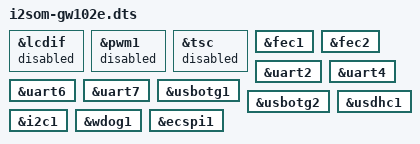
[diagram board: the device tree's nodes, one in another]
/*
 * Copyright (C) 2017 i2SOM Team.
 *
 * This program is free software; you can redistribute it and/or modify
 * it under the terms of the GNU General Public License version 2 as
 * published by the Free Software Foundation.
 */
/dts-v1/;

#include "i2s6uby2-emmc.dtsi"
#include "i2som-gw102e.dtsi"

&lcdif {
	status = "disabled";
};

&pwm1 {
	status = "disabled";
};

&tsc {
	status = "disabled";
};

&fec1 {
	status = "okay";
};

&fec2 {
	status = "okay";
};

&uart2 {
	status = "okay";
};

&uart4 {
	status = "okay";
};

&uart6 {
	status = "okay";
};

&uart7 {
	status = "okay";
};

&usbotg1 {
	status = "okay";
};

&usbotg2 {
	status = "okay";
};

&usdhc1 {
	status = "okay";
};

&i2c1 {
	status = "okay";
};

&wdog1 {
	status = "okay";
};

&ecspi1 {
	status = "okay";
};
